# CH585SFR register map
Vendor: WCH Ltd.; Series: CH58x; File version: 1.0
CPU: RISC-V r0p0, little endian, no MPU, no FPU, 2 interrupt priority bits
Registers are 8-bit, Read or Write, reset 0x0 unless marked. A register's access mark holds for its fields unless they carry their own. Offsets are from the block's base; [hi:lo] are bit positions; {n}, {i} and the like mark numbered series.

## SYS — System Control Register
Base 0x40001000
0x00 R32_IWDG_KR 32-bit wo reset not defined — WO, Watchdog key register, SAM
  [15:0] IWDG_KR — RO,KEY [15:0]: Key value
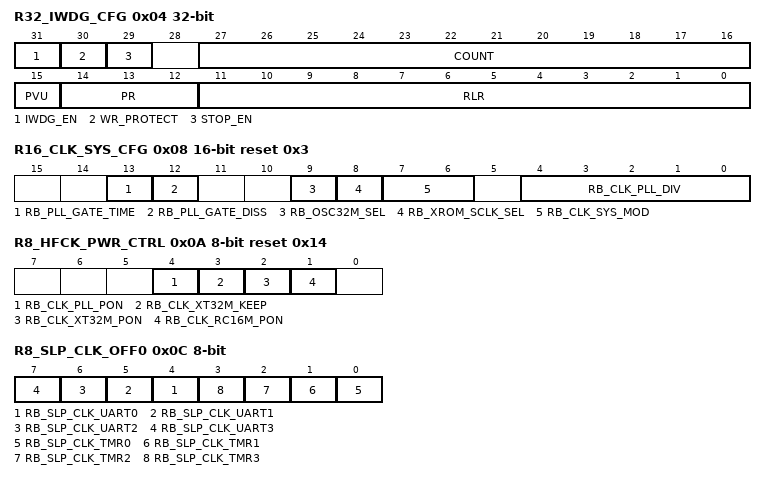
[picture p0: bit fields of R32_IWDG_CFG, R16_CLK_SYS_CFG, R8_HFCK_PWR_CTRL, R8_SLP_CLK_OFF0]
0x04 R32_IWDG_CFG 32-bit Read and Write reset not defined — RW, Watchdog configuration register, SAM
  [31] IWDG_EN ro — RW, Watch dog start switch: 1: ON; 0: Close
  [30] WR_PROTECT ro — RW, Write protection
  [29] STOP_EN ro — RW, Watchdog stop enabled (with write protection)
  [27:16] COUNT ro — RO, Watchdog countdown counter
  [15] PVU ro — RO, Configure register update flag bit (with write protection)
  [14:12] PR — RO, Pre division factor (with write protection)
  [11:0] RLR — RW, RL [11:0]: Watchdog counter reload
0x08 R16_CLK_SYS_CFG 16-bit Read or Write under safe Accessing mode reset 0x3 — RWA, system clock configuration, SAM
  [13] RB_PLL_GATE_TIME — RWA, When switching the PLL clock source, turn off the time selection of the PLL clock
  [12] RB_PLL_GATE_DISS — RWA, Do you turn off the PLL clock when switching the PLL clock source
  [9] RB_OSC32M_SEL — RWA, Selection of PLL clock source
  [8] RB_XROM_SCLK_SEL — RWA, XROM clock source
  [7:6] RB_CLK_SYS_MOD — RWA, system clock source mode: 00=divided from 32MHz
  [4:0] RB_CLK_PLL_DIV — RWA, output clock divider from PLL or CK32M
0x0A R8_HFCK_PWR_CTRL Read or Write under safe Accessing mode reset 0x14 — RWA, High frequency clock module power control register, SAM
  [4] RB_CLK_PLL_PON — RWA, PLL power control bit
  [3] RB_CLK_XT32M_KEEP — RWA, Used to control the stopping of the clock system in pause mode
  [2] RB_CLK_XT32M_PON — RWA, External 32MHz oscillator HSE power control bit
  [1] RB_CLK_RC16M_PON — RWA,Enable items for the internal 16MHz oscillator HSI
0x0C R8_SLP_CLK_OFF0 Read or Write under safe Accessing mode — RWA, sleep clock off control byte 0, SAM
  [n+4] RB_SLP_CLK_UART{n} (n=0..3) — RWA, UART{n} clock source
  [n] RB_SLP_CLK_TMR{n} (n=0..3) — RWA, Timer {n} clock source
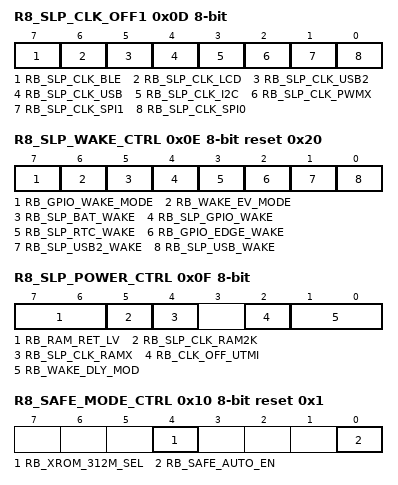
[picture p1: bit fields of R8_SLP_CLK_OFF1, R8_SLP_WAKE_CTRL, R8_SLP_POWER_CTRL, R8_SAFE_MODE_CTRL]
0x0D R8_SLP_CLK_OFF1 Read or Write under safe Accessing mode — RWA, sleep clock off control byte 1, SAM
  [7] RB_SLP_CLK_BLE — RWA, close BLE clock
  [6] RB_SLP_CLK_LCD — RWA, close LCD clock
  [5] RB_SLP_CLK_USB2 — RWA, close USB2 clock
  [4] RB_SLP_CLK_USB — RWA, close USB clock
  [3] RB_SLP_CLK_I2C — RWA, close I2C clock
  [2] RB_SLP_CLK_PWMX — RWA, close PWMx clock
  [1] RB_SLP_CLK_SPI1 — RWA, close SPI1 clock
  [0] RB_SLP_CLK_SPI0 — RWA, close SPI0 clock
0x0E R8_SLP_WAKE_CTRL Read or Write under safe Accessing mode reset 0x20 — RWA, wake control, SAM
  [7] RB_GPIO_WAKE_MODE — RWA, enable GPIO wake-up mode
  [6] RB_WAKE_EV_MODE — RWA, event wakeup mode
  [5] RB_SLP_BAT_WAKE — RWA, enable BAT waking
  [4] RB_SLP_GPIO_WAKE — RWA, enable GPIO waking
  [3] RB_SLP_RTC_WAKE — RWA, enable RTC waking
  [2] RB_GPIO_EDGE_WAKE — RWA, GPIO edge wake-up mode selection
  [1] RB_SLP_USB2_WAKE — RWA, enable USB2 waking
  [0] RB_SLP_USB_WAKE — RWA, enable USB waking
0x0F R8_SLP_POWER_CTRL Read or Write under safe Accessing mode — RWA, peripherals power down control, SAM
  [7:6] RB_RAM_RET_LV — RWA, SRAM retention voltage selection
  [5] RB_SLP_CLK_RAM2K — RWA, close retention 2KB SRAM clock
  [4] RB_SLP_CLK_RAMX — RWA, close main SRAM clock
  [2] RB_CLK_OFF_UTMI — RWA, Utmi_clk clock source
  [1:0] RB_WAKE_DLY_MOD — RWA, wakeup delay time selection
0x10 R8_SAFE_MODE_CTRL Read or Write under safe Accessing mode reset 0x1 — RWA, Secure Access Mode Control Register, SAM
  [4] RB_XROM_312M_SEL Read or Write — RWA, XROM Clock Selection
  [0] RB_SAFE_AUTO_EN Read or Write — RWA, Enable automatic shutdown of security register.
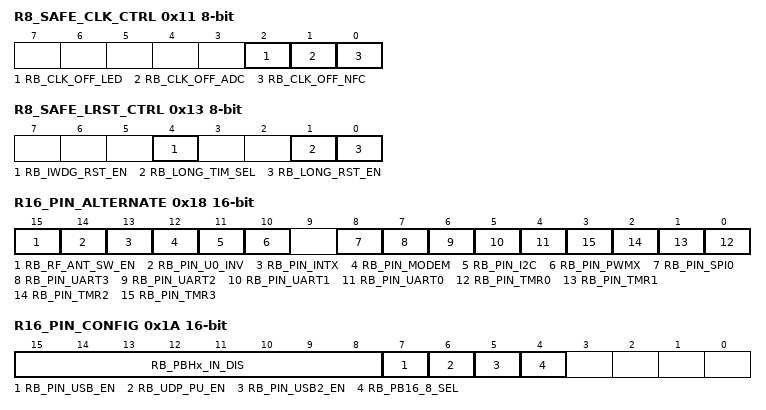
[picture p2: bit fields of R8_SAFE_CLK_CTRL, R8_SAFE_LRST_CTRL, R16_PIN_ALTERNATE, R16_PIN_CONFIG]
0x11 R8_SAFE_CLK_CTRL Read or Write under safe Accessing mode — RWA, Secure access to clock control registers, SAM
  [2] RB_CLK_OFF_LED — RWA, LED clock off enable
  [1] RB_CLK_OFF_ADC — RWA, ADC clock off enable
  [0] RB_CLK_OFF_NFC — RWA, NFC clock off enable.
0x12 R8_SAFE_DEBUG_CTRL Read or Write under safe Accessing mode — RWA, Secure Access Debugging Control Register, SAM
  [4] RB_DEBUG_DIS — RWA, DEBUG disable enable.
0x13 R8_SAFE_LRST_CTRL Read or Write under safe Accessing mode — RWA, Long term reset control register for secure access, SAM
  [4] RB_IWDG_RST_EN — RWA, Independent watchdog reset enable.
  [1] RB_LONG_TIM_SEL — RWA, Long reset time selection.
  [0] RB_LONG_RST_EN — RWA, Long reset enable.
0x18 R16_PIN_ALTERNATE 16-bit — RW, function pin alternate configuration
  [15] RB_RF_ANT_SW_EN — RW, RF antenna switch control output enable
  [14] RB_PIN_U0_INV — RW, UART0 input/output inversion enable
  [13] RB_PIN_INTX — RW, INT24/INT25 function pin mapping selection bit
  [12] RB_PIN_MODEM — RW, DSR/DTR alternate pin enable
  [11] RB_PIN_I2C — RW, SCL/SDA alternate pin enable
  [10] RB_PIN_PWMX — RW, PWM4/PWM5/PWM7/PWM8/PWM9 alternate pin enable
  [8] RB_PIN_SPI0 — RW, SCS/SCK0/MOSI/MISO alternate pin enable
  [7] RB_PIN_UART3 — RW, RXD3/TXD3 alternate pin enable
  [6] RB_PIN_UART2 — RW, RXD2/TXD2 alternate pin enable
  [5] RB_PIN_UART1 Read or  Write — RW, RXD1/TXD1 alternate pin enable
  [4] RB_PIN_UART0 — RW, RXD0/TXD0 alternate pin enable
  [n] RB_PIN_TMR{n} (n=0..3) — RW, TMR{n} alternate pin enable
0x1A R16_PIN_CONFIG 16-bit — RW, Function pin configuration registere
  [15:8] RB_PBHx_IN_DIS — RW, PB16~PB23 channel pin digital input disabled
  [7] RB_PIN_USB_EN — RW, Full speed USB pin enable
  [6] RB_UDP_PU_EN — RW, Full speed USB UD+pin internal pull-up resistor enable
  [5] RB_PIN_USB2_EN — RW, Enable high-speed USB pins
  [4] RB_PB16_8_SEL — RW, Selection of interrupt pins for PB8 and PB16
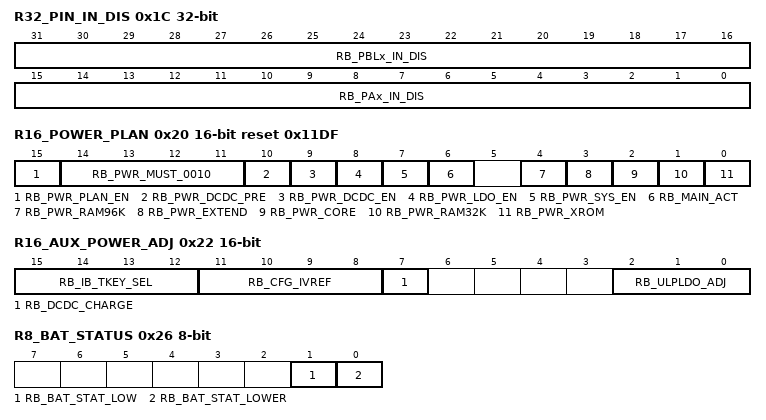
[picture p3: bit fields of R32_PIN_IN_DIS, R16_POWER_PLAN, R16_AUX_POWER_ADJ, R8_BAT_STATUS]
0x1C R32_PIN_IN_DIS 32-bit — RW, Function pin digital input disable register
  [31:16] RB_PBLx_IN_DIS — RW, PB0~PB15 channel pin digital input disabled
  [15:0] RB_PAx_IN_DIS — RW, PA0~PA15 channel pin digital input disabled
0x20 R16_POWER_PLAN 16-bit Read or Write under safe Accessing mode reset 0x11DF — RWA, power plan before sleep instruction, SAM
  [15] RB_PWR_PLAN_EN — RWA, Enable sleep power planning and control
  [14:11] RB_PWR_MUST_0010 — RWA, Must write 0010.
  [10] RB_PWR_DCDC_PRE — RWA, DC/DC converter pre-enable
  [9] RB_PWR_DCDC_EN — RWA, DC/DC converter enable
  [8] RB_PWR_LDO_EN — RWA, Internal LDO control
  [7] RB_PWR_SYS_EN — RWA, power for system
  [6] RB_MAIN_ACT — RWA, Main power selection
  [4] RB_PWR_RAM96K — RWA, SRAM power supply for RAM24K
  [3] RB_PWR_EXTEND — RWA, power retention for USB and BLE
  [2] RB_PWR_CORE — RWA, power retention for core and base peripherals
  [1] RB_PWR_RAM32K — RWA, SRAM power supply for RAM2K
  [0] RB_PWR_XROM — RWA, power for FlashROM
0x22 R16_AUX_POWER_ADJ 16-bit Read or Write under safe Accessing mode reset not defined — RWA, aux power adjust control, SAM
  [15:12] RB_IB_TKEY_SEL — RWA, TouchKey bias current, used to stabilize I/O potential and prevent accidental wake-up
  [11:8] RB_CFG_IVREF — RWA, retain. The original value must be kept unchanged when writing
  [7] RB_DCDC_CHARGE — RWA, Low power auxiliary DC-DC enable bit
  [2:0] RB_ULPLDO_ADJ — RWA, Output voltage regulation value of auxiliary power supply for ultra-low power consumption LDO
0x24 R8_BAT_DET_CTRL Read or Write under safe Accessing mode — RWA, battery voltage detector control, SAM
  [3] RB_BAT_LOW_IE — RWA, interrupt enable for battery low voltage
  [2] RB_BAT_LOWER_IE — RWA, Battery ultra-low voltage interrupt enable
  [2] RB_BAT_LOWER_IE — RWA, interrupt enable for battery lower voltage
  [1] RB_BAT_LOW_VTHX — RWA, When RB_BAT_MON_EN=1, set low power consumption
  [0] RB_BAT_DET_EN — RWA, When RB_BAT_MON_EN=0, it is enabled by high-precision battery voltage detection function
0x25 R8_BAT_DET_CFG Read or Write under safe Accessing mode reset 0x2 — RWA, battery voltage detector configuration, SAM
  [1:0] RB_BAT_LOW_VTH — RWA, select threshold voltage of battery voltage low
0x26 R8_BAT_STATUS ro — RO, battery status
  [1] RB_BAT_STAT_LOW — RO, battery low voltage status, high action
  [0] RB_BAT_STAT_LOWER — RO, battery lower voltage status, high action
0x2C R16_INT32K_TUNE 16-bit Read or Write under safe Accessing mode reset 0x1011 — RWA, internal 32KHz oscillator tune control, SAM
  [12:0] RB_INT32K_TUNE — RWA, Internal RC 32KHz clock frequency calibration value
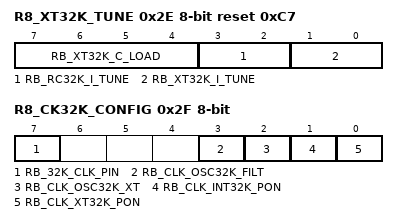
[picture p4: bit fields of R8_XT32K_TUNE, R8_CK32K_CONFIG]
0x2E R8_XT32K_TUNE Read or Write under safe Accessing mode reset 0xC7 — RWA, External 32KHz oscillator tune control, SAM
  [7:4] RB_XT32K_C_LOAD — RWA, Choose a built-in load capacitor that matches the external 32KHz crystal
  [3:2] RB_RC32K_I_TUNE — RWA, RC32K adjustment bit, internal 32KHz oscillator bias current selection
  [1:0] RB_XT32K_I_TUNE — RWA, Selection of bias current for external 32KHz oscillator
0x2F R8_CK32K_CONFIG Read or Write under safe Accessing mode reset not defined — RWA, 32KHz oscillator configure
  [7] RB_32K_CLK_PIN — RO, 32KHz oscillator clock pin status
  [3] RB_CLK_OSC32K_FILT — RWA, internal 32KHz oscillator low noise mode enable
  [2] RB_CLK_OSC32K_XT — RWA, 32KHz oscillator source selection: 0=RC, 1=XT
  [1] RB_CLK_INT32K_PON — RWA, internal 32KHz oscillator power on
  [0] RB_CLK_XT32K_PON — RWA, external 32KHz oscillator power on
